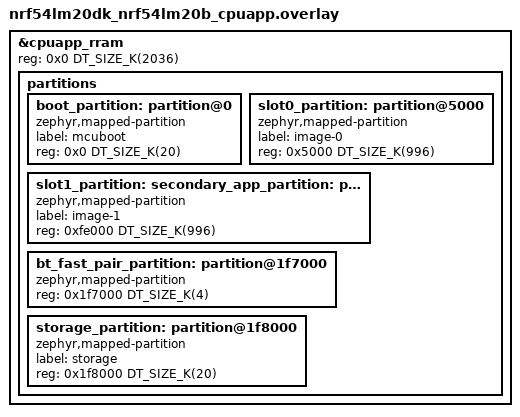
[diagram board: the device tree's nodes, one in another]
/*
 * Copyright (c) 2026 Nordic Semiconductor ASA
 *
 * SPDX-License-Identifier: LicenseRef-Nordic-5-Clause
 */

&cpuapp_rram {
	/* Application does not use cpuflpr core. Assign whole RRAM to cpuapp. */
	reg = <0x0 DT_SIZE_K(2036)>;

	/* Redefine the "partitions" DTS node. */
	/delete-node/ partitions;

	partitions {
		ranges;
		#address-cells = <1>;
		#size-cells = <1>;

		boot_partition: partition@0 {
			compatible = "zephyr,mapped-partition";
			label = "mcuboot";
			reg = <0x0 DT_SIZE_K(20)>;
		};

		slot0_partition: partition@5000 {
			compatible = "zephyr,mapped-partition";
			label = "image-0";
			reg = <0x5000 DT_SIZE_K(996)>;
		};

		slot1_partition: partition@fe000 {
			compatible = "zephyr,mapped-partition";
			label = "image-1";
			reg = <0xfe000 DT_SIZE_K(996)>;
		};

		bt_fast_pair_partition: partition@1f7000 {
			compatible = "zephyr,mapped-partition";
			reg = <0x1f7000 DT_SIZE_K(4)>;
		};

		storage_partition: partition@1f8000 {
			compatible = "zephyr,mapped-partition";
			label = "storage";
			reg = <0x1f8000 DT_SIZE_K(20)>;
		};
	};
};

secondary_app_partition: &slot1_partition {};
